# R7FA2L209 register map
Vendor: Renesas Electronics Corporation; Series: RA2; File version: 1.10.02
CPU: CM23 r1p0, little endian, MPU, no FPU, VTOR, 2 interrupt priority bits, 32 interrupts
Registers are 8-bit, read-write, reset 0x0 unless marked. A register's access mark holds for its fields unless they carry their own. Offsets are from the block's base; [hi:lo] are bit positions; {n}, {i} and the like mark numbered series; 'fields as' and 'values as' point back to an identical list.

## USBFS — USB 2.0 Full-Speed Module
Base 0x40090000
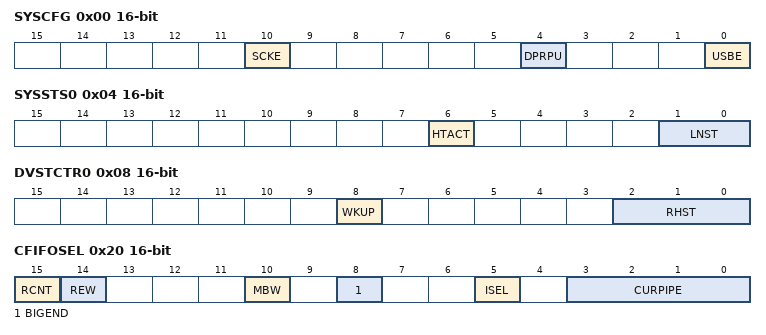
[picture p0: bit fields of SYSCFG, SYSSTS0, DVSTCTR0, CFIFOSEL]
0x00 SYSCFG 16-bit — System Configuration Control Register
  [10] SCKE — USB Clock Enable
    0=Stop clock supply to the USBFS; 1=Enable clock supply to the USBFS
  [4] DPRPU — D+ Line Resistor Control
    0=Disable line pull-up; 1=Enable line pull-up
  [0] USBE — USBFS Operation Enable
    0=Disable; 1=Enable
0x04 SYSSTS0 16-bit ro — System Configuration Status Register 0
  [6] HTACT — USB Host Sequencer Status Monitor
    0=Host sequencer completely stopped; 1=Host sequencer not completely stopped
  [1:0] LNST — USB Data Line Status Monitor
0x08 DVSTCTR0 16-bit — Device State Control Register 0
  [8] WKUP — Wakeup Output
    0=Do not output remote wakeup signal; 1=Output remote wakeup signal
  [2:0] RHST ro — USB Bus Reset Status
    0=In device controller mode: Communication speed indeterminate; 1=In device controller mode: USB bus reset in progress; 2=In device controller mode: USB bus reset in progress or full-speed connection; 3=Setting prohibited; other=Others (In device controller mode: Setting prohibited)
0x14 CFIFO 16-bit — CFIFO Port Register
  [15:0] FIFOPORT
0x14 CFIFOL (alternate view of CFIFO) — CFIFO Port Register
  [7:0] FIFOPORT
{0x18+4i} D{i}FIFO (i=0..1) 16-bit — D{i}FIFO Port Register
  [15:0] FIFOPORT
{0x18+4i} D{i}FIFOL (i=0..1) (alternate view of D{i}FIFO) — D{i}FIFO Port Register
  [7:0] FIFOPORT
0x20 CFIFOSEL 16-bit — CFIFO Port Select Register
  [15] RCNT — Read Count Mode
    0=The DTLN[8:0] bits (CFIFOCTR.DTLN[8:0], D0FIFOCTR.DTLN[8:0], D1FIFOCTR.DTLN[8:0]) are cleared when all receive data is read from the CFIFO. In double buffer mode, the DTLN[8:0] value is cleared when all data is read from only a single plane.; 1=The DTLN[8:0] bits are decremented each time the receive data is read from the CFIFO
  [14] REW wo — Buffer Pointer Rewind
    0=Do not rewind buffer pointer; 1=Rewind buffer pointer
  [10] MBW — CFIFO Port Access Bit Width
    0=8-bit width; 1=16-bit width
  [8] BIGEND — CFIFO Port Endian Control
    0=Little endian; 1=Big endian
  [5] ISEL — CFIFO Port Access Direction When DCP Is Selected
    0=Select reading from the FIFO buffer; 1=Select writing to the FIFO buffer
  [3:0] CURPIPE — CFIFO Port Access Pipe Specification
    0=Default Control Pipe; {v}=Pipe {v} (v=1..9); other=Others (Setting prohibited)
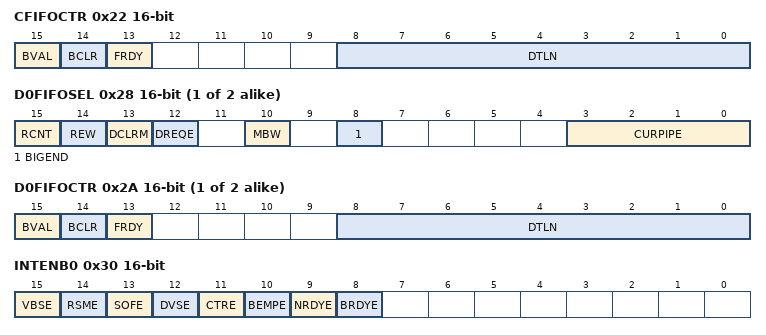
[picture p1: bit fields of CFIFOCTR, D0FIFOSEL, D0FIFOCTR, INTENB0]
0x22 CFIFOCTR 16-bit — CFIFO Port Control Register
  [15] BVAL — Buffer Memory Valid Flag
    0=Invalid (writing 0 has no effect); 1=Writing ended
  [14] BCLR wo — CPU Buffer Clear
    0=No operation; 1=Clear FIFO buffer on the CPU side
  [13] FRDY ro — FIFO Port Ready
    0=FIFO port access disabled; 1=FIFO port access enabled
  [8:0] DTLN ro — Receive Data Length
{0x28+4i} D{i}FIFOSEL (i=0..1) 16-bit — D{i}FIFO Port Select Register
  [15] RCNT — Read Count Mode
    0=Clear DTLN[8:0] bits in (CFIFOCTR.DTLN[8:0], D0FIFOCTR.DTLN[8:0], D1FIFOCTR.DTLN[8:0]) when all receive data is read from DnFIFO (after read of a single plane in double buffer mode); 1=Decrement DTLN[8:0] bits each time receive data is read from DnFIFO
  [14] REW wo — Buffer Pointer Rewind
    0=Do not rewind buffer pointer; 1=Rewind buffer pointer
  [13] DCLRM — Auto Buffer Memory Clear Mode Accessed after Specified Pipe Data is Read
    0=Disable auto buffer clear mode; 1=Enable auto buffer clear mode
  [12] DREQE — DTC Transfer Request Enable
    0=Disable DTC transfer request; 1=Enable DTC transfer request
  [10] MBW — FIFO Port Access Bit Width
    0=8-bit width; 1=16-bit width
  [8] BIGEND — FIFO Port Endian Control
    0=Little endian; 1=Big endian
  [3:0] CURPIPE — FIFO Port Access Pipe Specification
    values as CFIFOSEL.CURPIPE
{0x2A+4i} D{i}FIFOCTR (i=0..1) 16-bit — D{i}FIFO Port Control Register
  [15] BVAL — Buffer Memory Valid Flag
    0=Invalid (writing 0 has no effect); 1=Writing ended
  [14] BCLR — CPU Buffer Clear
    0=No operation; 1=Clear FIFO buffer on the CPU side
  [13] FRDY ro — FIFO Port Ready
    0=FIFO port access disabled; 1=FIFO port access enabled
  [8:0] DTLN ro — Receive Data Length
0x30 INTENB0 16-bit — Interrupt Enable Register 0
  [all] fields
    0=Disable interrupt request; 1=Enable interrupt request
  [15] VBSE — VBUS Interrupt Enable
  [14] RSME — Resume Interrupt Enable
  [13] SOFE — Frame Number Update Interrupt Enable
  [12] DVSE — Device State Transition Interrupt Enable
  [11] CTRE — Control Transfer Stage Transition Interrupt Enable
  [10] BEMPE — Buffer Empty Interrupt Enable
  [9] NRDYE — Buffer Not Ready Response Interrupt Enable
  [8] BRDYE — Buffer Ready Interrupt Enable
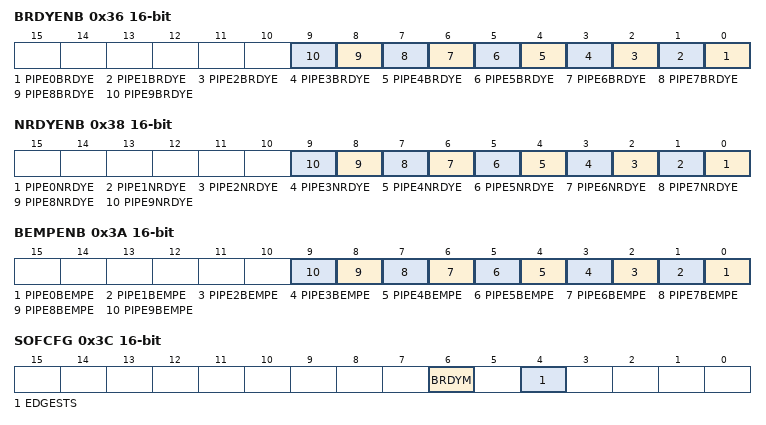
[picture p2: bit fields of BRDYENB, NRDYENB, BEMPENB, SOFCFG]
0x36 BRDYENB 16-bit — BRDY Interrupt Enable Register
  [all] fields
    0=Disable interrupt request; 1=Enable interrupt request
  [n] PIPE{n}BRDYE (n=0..9) — BRDY Interrupt Enable for Pipe {n}
0x38 NRDYENB 16-bit — NRDY Interrupt Enable Register
  [all] fields
    0=Disable interrupt request; 1=Enable interrupt request
  [n] PIPE{n}NRDYE (n=0..9) — NRDY Interrupt Enable for Pipe {n}
0x3A BEMPENB 16-bit — BEMP Interrupt Enable Register
  [all] fields
    0=Disable interrupt request; 1=Enable interrupt request
  [n] PIPE{n}BEMPE (n=0..9) — BEMP Interrupt Enable for Pipe {n}
0x3C SOFCFG 16-bit — SOF Output Configuration Register
  [6] BRDYM — BRDY Interrupt Status Clear Timing
    0=Clear BRDY flag by software; 1=Clear BRDY flag by the USBFS through a data read from the FIFO buffer or data write to the FIFO buffer
  [4] EDGESTS ro — Edge Interrupt Output Status Monitor
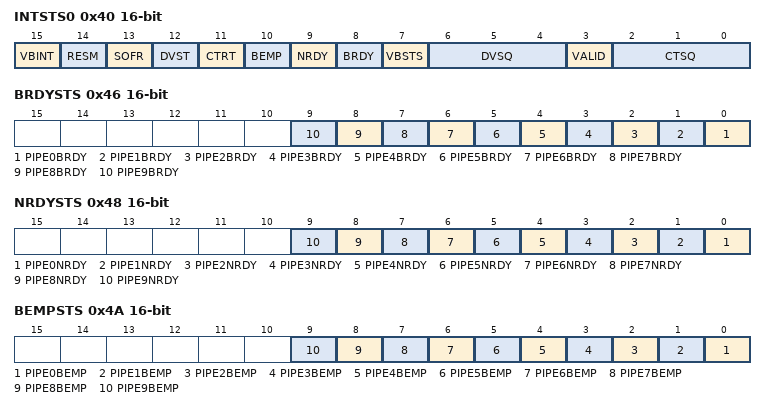
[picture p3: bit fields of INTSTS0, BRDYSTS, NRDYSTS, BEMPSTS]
0x40 INTSTS0 16-bit (reset mask 0xEF6F) — Interrupt Status Register 0
  [15] VBINT — VBUS Interrupt Status
    0=No VBUS interrupt occurred; 1=VBUS interrupt occurred
  [14] RESM — Resume Interrupt Status
    0=No resume interrupt occurred; 1=Resume interrupt occurred
  [13] SOFR — Frame Number Refresh Interrupt Status
    0=No SOF interrupt occurred; 1=SOF interrupt occurred
  [12] DVST — Device State Transition Interrupt Status
    0=No device state transition interrupt occurred; 1=Device state transition interrupt occurred
  [11] CTRT — Control Transfer Stage Transition Interrupt Status
    0=No control transfer stage transition interrupt occurred; 1=Control transfer stage transition interrupt occurred
  [10] BEMP ro — Buffer Empty Interrupt Status
    0=No BEMP interrupt occurred; 1=BEMP interrupt occurred
  [9] NRDY ro — Buffer Not Ready Interrupt Status
    0=No NRDY interrupt occurred; 1=NRDY interrupt occurred
  [8] BRDY ro — Buffer Ready Interrupt Status
    0=No BRDY interrupt occurred; 1=BRDY interrupt occurred
  [7] VBSTS ro — VBUS Input Status
    0=USB_VBUS pin is low; 1=USB_VBUS pin is high
  [6:4] DVSQ ro — Device State
    0=Powered state; 1=Default state; 2=Address state; 3=Configured state; other=Others (Suspend state)
  [3] VALID — USB Request Reception
    0=Setup packet not received; 1=Setup packet received
  [2:0] CTSQ ro — Control Transfer Stage
    0=Idle or setup stage; 1=Control read data stage; 2=Control read status stage; 3=Control write data stage; 4=Control write status stage; 5=Control write (no data) status stage; 6=Control transfer sequence error
0x46 BRDYSTS 16-bit — BRDY Interrupt Status Register
  [all] fields
    0=No BRDY interrupt occurred; 1=BRDY interrupt occurred
  [n] PIPE{n}BRDY (n=0..9) — BRDY Interrupt Status for Pipe {n}
0x48 NRDYSTS 16-bit — NRDY Interrupt Status Register
  [all] fields
    0=No NRDY interrupt occurred; 1=NRDY interrupt occurred
  [n] PIPE{n}NRDY (n=0..9) — NRDY Interrupt Status for Pipe {n}
0x4A BEMPSTS 16-bit — BEMP Interrupt Status Register
  [all] fields
    0=No BEMP interrupt occurred; 1=BEMP interrupt occurred
  [n] PIPE{n}BEMP (n=0..9) — BEMP Interrupt Status for Pipe {n}
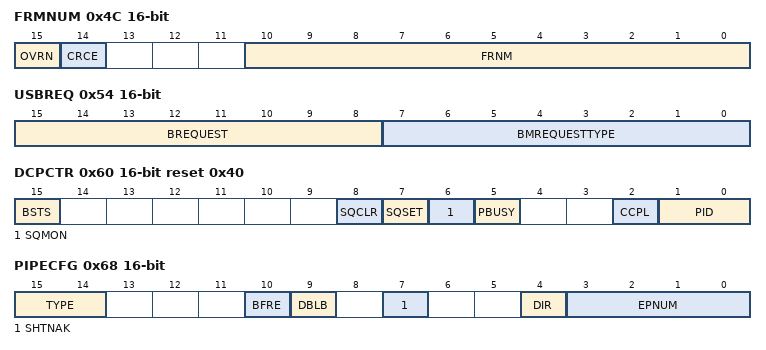
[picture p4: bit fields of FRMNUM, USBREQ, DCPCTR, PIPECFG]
0x4C FRMNUM 16-bit — Frame Number Register
  [15] OVRN — Overrun/Underrun Detection Status
    0=No error occurred; 1=Error occurred
  [14] CRCE — Receive Data Error
    0=No error occurred; 1=Error occurred
  [10:0] FRNM ro — Frame Number
0x50 USBADDR 16-bit — USB Address Register
  [6:0] USBADDR — USB Address
0x54 USBREQ 16-bit — USB Request Type Register
  [15:8] BREQUEST — Request
  [7:0] BMREQUESTTYPE — Request Type
0x56 USBVAL 16-bit — USB Request Value Register
  [15:0] WVALUE — Value
0x58 USBINDX 16-bit — USB Request Index Register
  [15:0] WINDEX — Index
0x5A USBLENG 16-bit — USB Request Length Register
  [15:0] WLENTUH — Length
0x5C DCPCFG 16-bit — DCP Configuration Register
  [7] SHTNAK — Pipe Disabled at End of Transfer
    0=Keep pipe open after transfer ends; 1=Disable pipe after transfer ends
0x5E DCPMAXP 16-bit reset 0x40 — DCP Maximum Packet Size Register
  [6:0] MXPS — Maximum Packet Size
0x60 DCPCTR 16-bit reset 0x40 — DCP Control Register
  [15] BSTS ro — Buffer Status
    0=Buffer access disabled; 1=Buffer access enabled
  [8] SQCLR — Sequence Toggle Bit Clear
    0=Invalid (writing 0 has no effect); 1=Clear the expected value for the next transaction to DATA0
  [7] SQSET — Sequence Toggle Bit Set
    0=Invalid (writing 0 has no effect); 1=Set the expected value for the next transaction to DATA1
  [6] SQMON ro — Sequence Toggle Bit Monitor
    0=DATA0; 1=ATA1
  [5] PBUSY ro — Pipe Busy
    0=DCP not used for the USB bus; 1=DCP in use for the USB bus
  [2] CCPL — Control Transfer End Enable
    0=Disable control transfer completion; 1=Enable control transfer completion
  [1:0] PID — Response PID
    0=NAK response; 1=BUF response (depends on the buffer state); 2=STALL response; 3=STALL response
0x64 PIPESEL 16-bit — Pipe Window Select Register
  [3:0] PIPESEL — Pipe Window Select
    0=No pipe selected; {v}=Pipe {v} (v=1..9); other=Others (Setting prohibited)
0x68 PIPECFG 16-bit — Pipe Configuration Register
  [15:14] TYPE — Transfer Type
    0=Pipe not used; 1=Pipes 1 and 2: Bulk transfer Pipes 3 to 5: Bulk transfer Pipes 6 to 9: Setting prohibited; 2=Pipes 1 and 2: Setting prohibited Pipes 3 to 5: Setting prohibited Pipes 6 to 9: Interrupt transfer; 3=Pipes 1 and 2: Isochronous transfer Pipes 3 to 5: Setting prohibited Pipes 6 to 9: Setting prohibited
  [10] BFRE — BRDY Interrupt Operation Specification
    0=Generate BRDY interrupt on transmitting or receiving data; 1=Generate BRDY interrupt on completion of reading data
  [9] DBLB — Double Buffer Mode
    0=Single buffer; 1=Double buffer
  [7] SHTNAK — Pipe Disabled at End of Transfer
    0=Continue pipe operation after transfer ends; 1=Disable pipe after transfer ends
  [4] DIR — Transfer Direction
    0=Receiving direction; 1=Transmitting direction
  [3:0] EPNUM — Endpoint Number
0x6C PIPEMAXP 16-bit (reset mask 0xFFBF) — Pipe Maximum Packet Size Register
  [8:0] MXPS — Maximum Packet Size
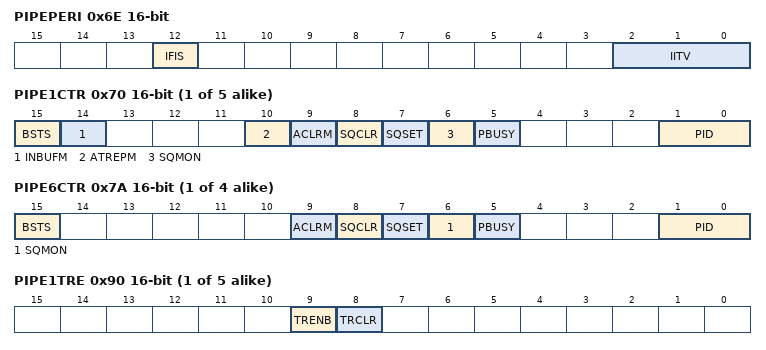
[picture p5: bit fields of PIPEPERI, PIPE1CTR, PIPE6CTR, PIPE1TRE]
0x6E PIPEPERI 16-bit — Pipe Cycle Control Register
  [12] IFIS — Isochronous IN Buffer Flush
    0=Do not flush buffer; 1=Flush buffer
  [2:0] IITV — Interval Error Detection Interval
{0x6E+2i} PIPE{i}CTR (i=1..5) 16-bit — PIPE{i} Control Registers
  [15] BSTS ro — Buffer Status
    0=Buffer access by the CPU disabled; 1=Buffer access by the CPU enabled
  [14] INBUFM ro — Transmit Buffer Monitor
    0=No data to be transmitted is in the FIFO buffer; 1=Data to be transmitted is in the FIFO buffer
  [10] ATREPM — Auto Response Mode
    0=Disable auto response mode; 1=Enable auto response mode
  [9] ACLRM — Auto Buffer Clear Mode
    0=Disable; 1=Enable (initialize all buffers)
  [8] SQCLR — Sequence Toggle Bit Clear
    values as DCPCTR.SQCLR
  [7] SQSET — Sequence Toggle Bit Set
    values as DCPCTR.SQSET
  [6] SQMON ro — Sequence Toggle Bit Confirmation
    0=DATA0; 1=DATA1
  [5] PBUSY ro — Pipe Busy
    0=Pipe n not in use for the transaction; 1=Pipe n in use for the transaction
  [1:0] PID — Response PID
    values as DCPCTR.PID
{0x6E+2i} PIPE{i}CTR (i=6..9) 16-bit — PIPE{i} Control Registers
  [15] BSTS ro — Buffer Status
    0=Buffer access disabled; 1=Buffer access enabled
  [9] ACLRM — Auto Buffer Clear Mode
    0=Disable; 1=Enable (all buffers initialized)
  [8] SQCLR wo — Sequence Toggle Bit Clear
    values as DCPCTR.SQCLR
  [7] SQSET wo — Sequence Toggle Bit Set
    0=Invalid (writing 0 has no effect); 1=Set the expected value for the next transaction to DATA0
  [6] SQMON ro — Sequence Toggle Bit Confirmation
    0=DATA0; 1=DATA1
  [5] PBUSY ro — Pipe Busy
    values as PIPE1CTR.PBUSY
  [1:0] PID — Response PID
    values as DCPCTR.PID
{0x8C+4i} PIPE{i}TRE (i=1..5) 16-bit — PIPE{i} Transaction Counter Enable Register
  [9] TRENB — Transaction Counter Enable
    0=Disable transaction counter; 1=Enable transaction counter
  [8] TRCLR — Transaction Counter Clear
    0=Invalid (writing 0 has no effect); 1=Clear counter value
{0x8E+4i} PIPE{i}TRN (i=1..5) 16-bit — PIPE{i} Transaction Counter Register
  [15:0] TRNCNT — Transaction Counter
